# GD32A72_A74x register map
File version: 1.0
CPU: CM7 r2p1, little endian, MPU, FPU, DSP, 4 interrupt priority bits
Registers are 32-bit, read-write, reset 0x0 unless marked. A register's access mark holds for its fields unless they carry their own. Offsets are from the block's base; [hi:lo] are bit positions; {n}, {i} and the like mark numbered series; 'fields as' and 'values as' point back to an identical list.

## IOC — Input Output Checker
Base 0x40023C00
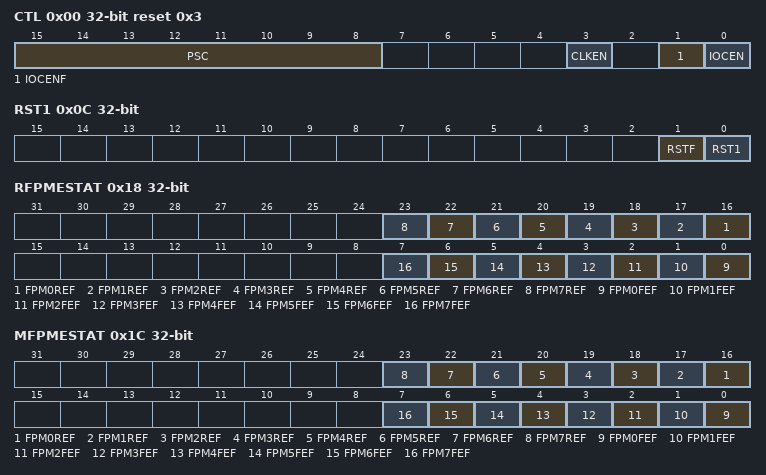
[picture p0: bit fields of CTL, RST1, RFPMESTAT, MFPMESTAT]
0x00 CTL access per field reset 0x3 — Control register
  [15:8] PSC rw — Clock prescaler selection
  [3] CLKEN rw — Clock enable
  [1] IOCENF ro — IOC status
  [0] IOCEN rw — IOC enable
0x04 RSTSTATC — Reset status clear register
  [0] RSTFC — Clear reset flag
0x08 RST0 — Reset register 0
  [0] RST0 — Reset IOC
0x0C RST1 access per field — Reset register 1
  [1] RSTF ro — IOC reset flag
  [0] RST1 rw — Reset IOC
0x18 RFPMESTAT — Reference signal FPM edge status register
  [n+16] FPM{n}REF (n=0..7) — FPM{n} rising edge flag
  [n] FPM{n}FEF (n=0..7) — FPM{n} falling edge fag
0x1C MFPMESTAT — Monitor signal FPM edge status register
  fields as RFPMESTAT
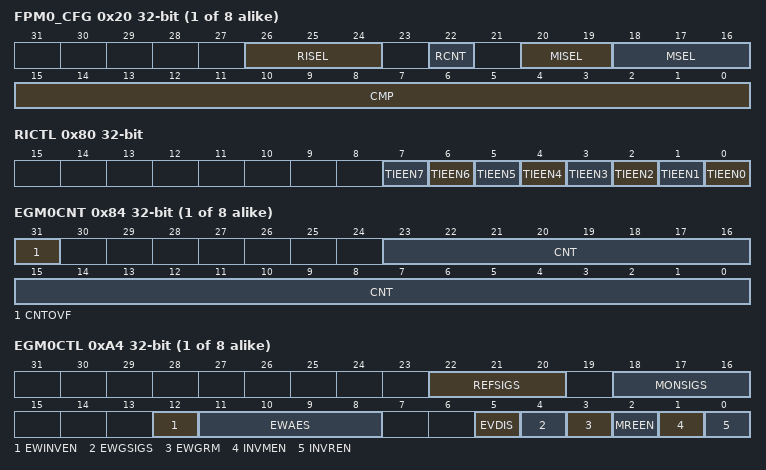
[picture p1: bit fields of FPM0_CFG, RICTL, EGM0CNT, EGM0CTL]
{0x20+4i} FPM{i}_CFG (i=0..7) — FPM{i} configuration register
  [26:24] RISEL — Reference input signal selection
  [22] RCNT — Reset the counter of timer
  [20:19] MISEL — Monitor input signal selection
  [18:16] MSEL — FPM mode
  [15:0] CMP — The value of 16 bit comparator
{0x40+4i} RFPM{i}CNT (i=0..7) — Reference signal FPM{i} count register
  [15:0] CNT — The value of the FPM timer counter
{0x60+4i} MFPM{i}CNT (i=0..7) — Monitor signal FPM {i} count register
  [15:0] CNT — The value of the FPM timer counter
0x80 RICTL — RSG combiner reference signal input control register
  [n] TIEEN{n} (n=0..7) — TRIGSEL input {n} selection for RSG combiner
{0x84+4i} EGM{i}CNT (i=0..7) — EGM count register
  [31] CNTOVF — Overflow flag
  [23:0] CNT — The value of event window count
{0xA4+4i} EGM{i}CTL (i=0..7) — EGM{i} control register
  [22:20] REFSIGS — Reference signal selection
  [18:16] MONSIGS — Monitor signal selection
  [12] EWINVEN — Invert event window
  [11:8] EWAES — Event window triger edge selection
  [5] EVDIS — Disable event generated
  [4] EWGSIGS — Event window generation signal selection
  [3] EWGRM — Event window generation run mode
  [2] MREEN — Enable monitor signal from the FPM compared with reference signal
  [1] INVMEN — Enable invert monitor signal
  [0] INVREN — Enable invert reference signal
{0xC4+4i} EGM{i}CFG (i=0..7) — EGM{i} configuration register
  [23:0] EWCTH — Event window count threshold
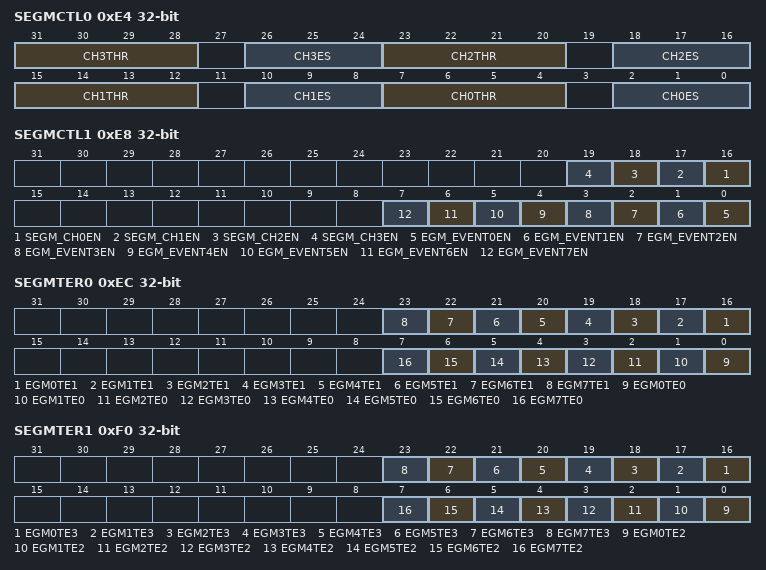
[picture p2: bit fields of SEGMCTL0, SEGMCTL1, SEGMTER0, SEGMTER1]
0xE4 SEGMCTL0 — SEGM control register 0
  [31:28] CH3THR — Refer to CH0THR[3:0] description
  [26:24] CH3ES — refer to ch0es[2:0] description
  [23:20] CH2THR — Refer to CH0THR[3:0] description
  [18:16] CH2ES — refer to ch0evs[2:0] description
  [15:12] CH1THR — Refer to CH0THR[3:0] description
  [10:8] CH1ES — refer to ch0es[2:0] description
  [7:4] CH0THR — SEGM Channel 0 event counter threshold
  [2:0] CH0ES — SEGM channel 0 event selection
0xE8 SEGMCTL1 — SEGM control register 1
  [n+16] SEGM_CH{n}EN (n=0..3) — Enable SEGM channel {n} selection
  [n] EGM_EVENT{n}EN (n=0..7) — Enable EGM_EVENT{n} selection
0xEC SEGMTER0 — SEGM generation event record register 0
  [n+16] EGM{n}TE1 (n=0..7) — EGM{n} triggered system event flag before EGM{n}TE0 updated
  [n] EGM{n}TE0 (n=0..7) — EGM{n} triggered system event flag at last time
0xF0 SEGMTER1 — SEGM generation event record register0
  [n+16] EGM{n}TE3 (n=0..7) — EGM{n} triggered system event flag before EGM{n}TE3 updated
  [n] EGM{n}TE2 (n=0..7) — EGM{n} triggered system event flag before EGM{n}TE2 updated
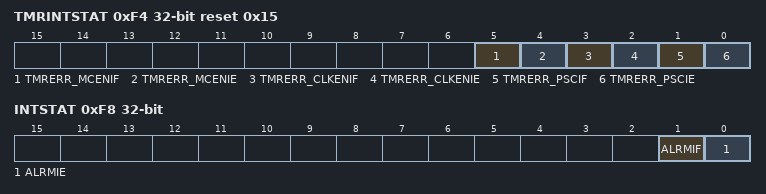
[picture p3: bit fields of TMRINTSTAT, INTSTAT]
0xF4 TMRINTSTAT reset 0x15 — TMR interrupt and status register
  [5] TMRERR_MCENIF — close enable tmr rectify error alarm flag
  [4] TMRERR_MCENIE — TMRERR_MCEN interrupt enable
  [3] TMRERR_CLKENIF — Clock control enable TMR rectify error alarm flag
  [2] TMRERR_CLKENIE — TMREER_CLKEN interrupt enable
  [1] TMRERR_PSCIF — Clock prescaler selection TMR rectify error alarm flag
  [0] TMRERR_PSCIE — TMRERR_PSC interrupt enable
0xF8 INTSTAT — Interrupt and status register
  [1] ALRMIF — segm event trigger flag
  [0] ALRMIE — Alarm interrupt enable
